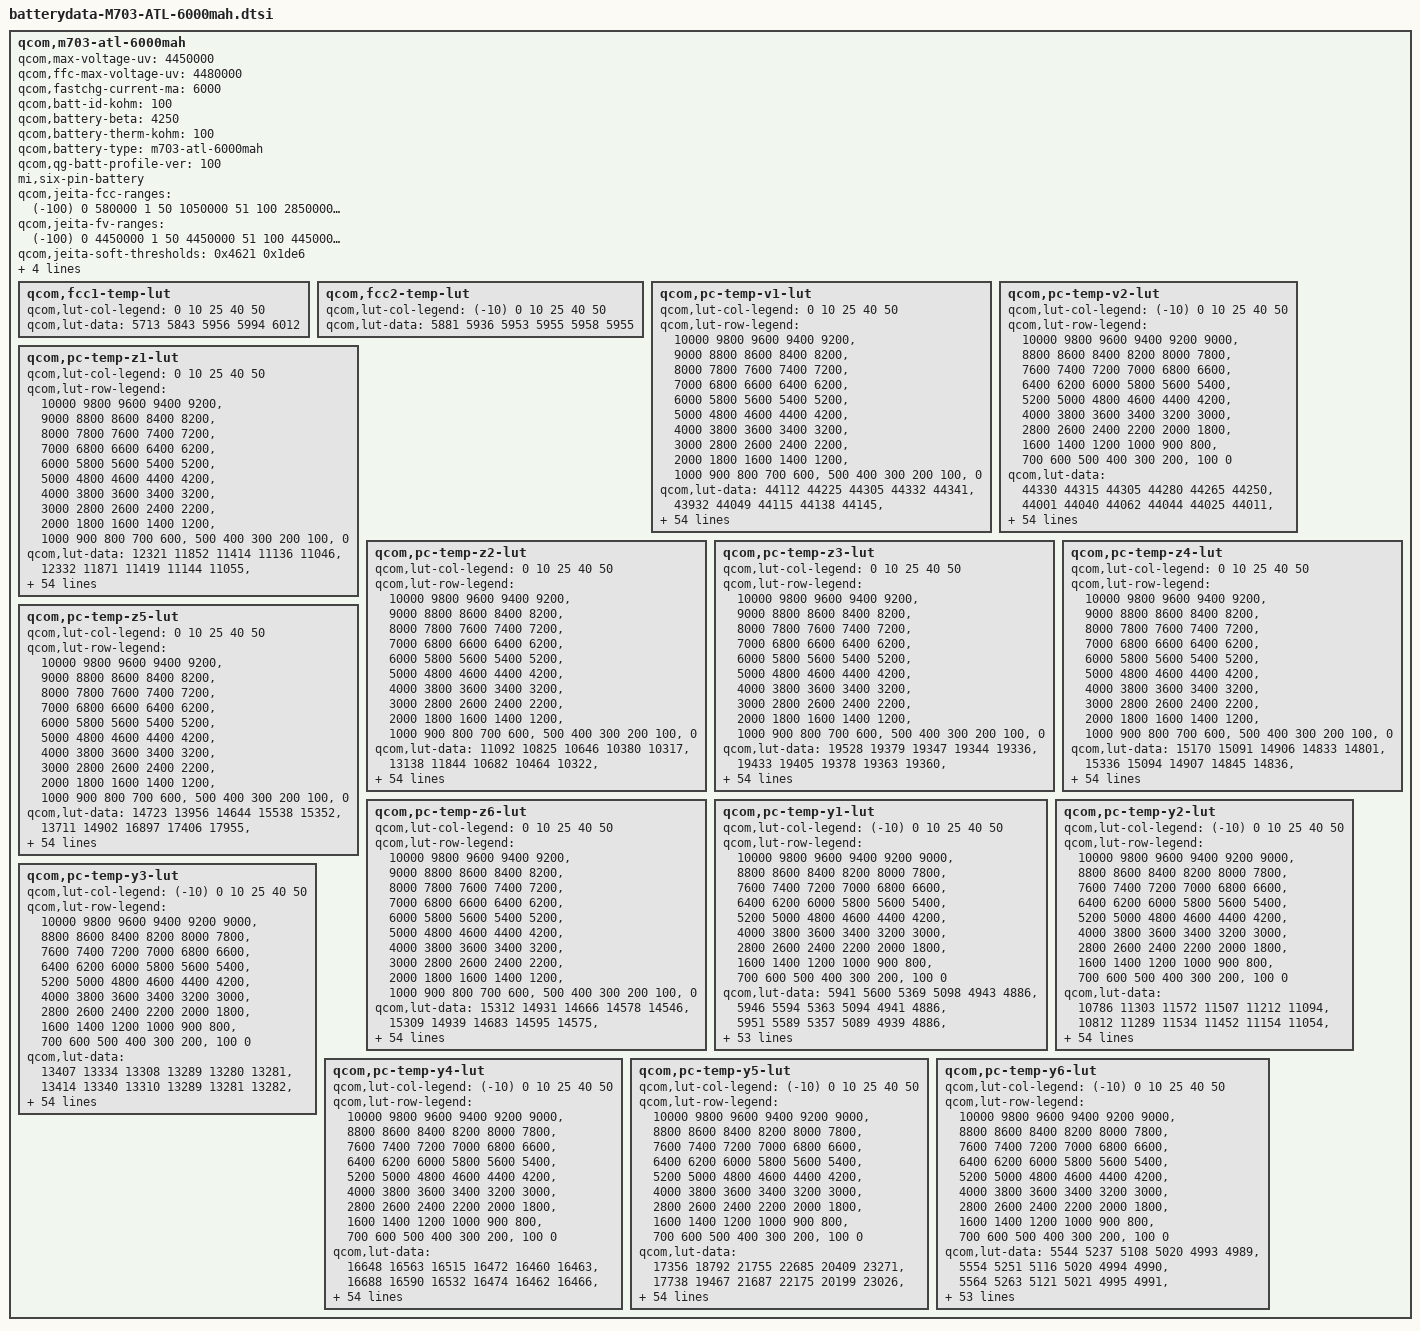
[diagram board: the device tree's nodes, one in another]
/*
 * Copyright (c) 2019, The Linux Foundation. All rights reserved.
 * Copyright (C) 2021 XiaoMi, Inc.
 *
 * This program is free software; you can redistribute it and/or modify
 * it under the terms of the GNU General Public License version 2 and
 * only version 2 as published by the Free Software Foundation.
 *
 * This program is distributed in the hope that it will be useful,
 * but WITHOUT ANY WARRANTY; without even the implied warranty of
 * MERCHANTABILITY or FITNESS FOR A PARTICULAR PURPOSE.  See the
 * GNU General Public License for more details.
 */

qcom,m703-atl-6000mah {
	qcom,max-voltage-uv = <4450000>;
	qcom,ffc-max-voltage-uv = <4480000>;
	//qcom,fg-cc-cv-threshold-uv = <4440000>;
	qcom,fastchg-current-ma = <6000>;
	qcom,batt-id-kohm = <100>;
	qcom,battery-beta = <4250>;
	qcom,battery-therm-kohm = <100>;
	qcom,battery-type = "m703-atl-6000mah";
	qcom,qg-batt-profile-ver = <100>;
	mi,six-pin-battery;

	qcom,jeita-fcc-ranges = <(-100)  0   580000
	                        1  50   1050000
				51  100  2850000
				101 150  4600000
				151 480  6000000
				481 580  2850000>;

	qcom,jeita-fv-ranges = <(-100)   0   4450000
                                1   50   4450000
				51  100  4450000
				101 150  4450000
				151 480  4480000
				481 580  4100000>;

	/* COOL = 15 degc, WARM = 48 degC */
	qcom,jeita-soft-thresholds = <0x4621 0x1de6>;
	/* COLD = -10 degC, HOT = 58 degC*/
	qcom,jeita-hard-thresholds = <0x6226 0x15f7>;
	/* COOL hys = 18 degC, WARM hys = 45 degC */
	qcom,jeita-soft-hys-thresholds = <0x4206 0x20b8>;
	qcom,jeita-soft-fcc-ua = <4600000 2900000>;
	qcom,jeita-soft-fv-uv = <4450000 4100000>;

	qcom,fcc1-temp-lut {
		qcom,lut-col-legend = <0 10 25 40 50>;
		qcom,lut-data = <5713 5843 5956 5994 6012>;
	};

	qcom,fcc2-temp-lut {
		qcom,lut-col-legend = <(-10) 0 10 25 40 50>;
		qcom,lut-data = <5881 5936 5953 5955 5958 5955>;
	};

	qcom,pc-temp-v1-lut {
		qcom,lut-col-legend = <0 10 25 40 50>;
		qcom,lut-row-legend = <10000 9800 9600 9400 9200>,
			<9000 8800 8600 8400 8200>,
			<8000 7800 7600 7400 7200>,
			<7000 6800 6600 6400 6200>,
			<6000 5800 5600 5400 5200>,
			<5000 4800 4600 4400 4200>,
			<4000 3800 3600 3400 3200>,
			<3000 2800 2600 2400 2200>,
			<2000 1800 1600 1400 1200>,
			<1000 900 800 700 600>,
			<500 400 300 200 100>,
			<0>;
		qcom,lut-data = <44112 44225 44305 44332 44341>,
			<43932 44049 44115 44138 44145>,
			<43712 43852 43919 43945 43953>,
			<43480 43638 43719 43747 43755>,
			<43249 43415 43513 43545 43552>,
			<43013 43185 43296 43334 43342>,
			<42777 42949 43065 43108 43117>,
			<42537 42710 42826 42872 42882>,
			<42299 42466 42586 42633 42644>,
			<42066 42224 42341 42388 42400>,
			<41836 41987 42100 42144 42157>,
			<41613 41754 41861 41904 41918>,
			<41393 41528 41627 41667 41682>,
			<41182 41307 41398 41435 41449>,
			<40980 41091 41173 41208 41219>,
			<40787 40886 40957 40988 40996>,
			<40593 40686 40748 40778 40781>,
			<40393 40493 40546 40574 40574>,
			<40197 40311 40360 40383 40381>,
			<40015 40122 40183 40208 40208>,
			<39852 39902 39984 40014 40021>,
			<39677 39661 39736 39753 39767>,
			<39430 39443 39488 39473 39485>,
			<39148 39242 39290 39274 39282>,
			<38976 39066 39117 39125 39134>,
			<38899 38939 38971 38994 39004>,
			<38839 38843 38853 38869 38875>,
			<38768 38753 38749 38756 38754>,
			<38693 38661 38648 38651 38647>,
			<38622 38571 38549 38553 38550>,
			<38556 38492 38461 38463 38462>,
			<38494 38418 38384 38384 38381>,
			<38438 38353 38314 38311 38306>,
			<38386 38297 38252 38241 38233>,
			<38338 38247 38196 38172 38163>,
			<38297 38202 38143 38105 38091>,
			<38260 38164 38092 38041 38020>,
			<38213 38120 38039 37975 37944>,
			<38139 38051 37968 37891 37849>,
			<38043 37954 37874 37784 37726>,
			<37935 37846 37769 37669 37598>,
			<37802 37719 37655 37556 37480>,
			<37649 37573 37521 37428 37352>,
			<37471 37401 37348 37257 37175>,
			<37304 37239 37201 37124 37054>,
			<37222 37138 37098 37047 36987>,
			<37188 37104 37068 37018 36960>,
			<37154 37084 37044 36992 36935>,
			<37121 37065 37025 36973 36911>,
			<37071 37017 36975 36913 36839>,
			<36890 36808 36737 36648 36551>,
			<36444 36353 36287 36204 36103>,
			<35857 35756 35698 35624 35520>,
			<35053 34929 34895 34832 34720>,
			<33706 33549 33645 33607 33478>,
			<30000 30000 30000 30000 30000>;
	};

	qcom,pc-temp-v2-lut {
		qcom,lut-col-legend = <(-10) 0 10 25 40 50>;
		qcom,lut-row-legend = <10000 9800 9600 9400 9200 9000>,
			<8800 8600 8400 8200 8000 7800>,
			<7600 7400 7200 7000 6800 6600>,
			<6400 6200 6000 5800 5600 5400>,
			<5200 5000 4800 4600 4400 4200>,
			<4000 3800 3600 3400 3200 3000>,
			<2800 2600 2400 2200 2000 1800>,
			<1600 1400 1200 1000 900 800>,
			<700 600 500 400 300 200>,
			<100 0>;
		qcom,lut-data = <44330 44315 44305 44280 44265 44250>,
			<44001 44040 44062 44044 44025 44011>,
			<43700 43782 43828 43815 43793 43781>,
			<43432 43546 43607 43594 43571 43561>,
			<43197 43334 43398 43381 43360 43352>,
			<42966 43119 43185 43164 43146 43139>,
			<42721 42884 42953 42931 42915 42910>,
			<42474 42640 42711 42691 42677 42674>,
			<42232 42395 42468 42449 42438 42436>,
			<41997 42147 42222 42204 42194 42194>,
			<41765 41902 41977 41960 41952 41952>,
			<41528 41663 41738 41721 41713 41713>,
			<41292 41431 41502 41486 41478 41476>,
			<41083 41209 41272 41255 41247 41244>,
			<40918 40997 41047 41029 41023 41020>,
			<40743 40791 40829 40810 40806 40803>,
			<40471 40592 40619 40600 40596 40592>,
			<40100 40396 40414 40397 40393 40387>,
			<39782 40170 40209 40203 40202 40195>,
			<39549 39888 40005 40025 40027 40019>,
			<39343 39603 39788 39835 39840 39833>,
			<39136 39357 39534 39585 39596 39594>,
			<38935 39130 39260 39300 39320 39325>,
			<38749 38933 39039 39075 39098 39105>,
			<38570 38761 38863 38902 38923 38930>,
			<38410 38608 38712 38754 38773 38779>,
			<38299 38472 38578 38623 38641 38646>,
			<38217 38349 38459 38508 38526 38530>,
			<38147 38237 38349 38402 38421 38422>,
			<38084 38130 38247 38303 38324 38321>,
			<38028 38039 38153 38213 38236 38229>,
			<37972 37973 38063 38131 38156 38149>,
			<37919 37921 37979 38055 38083 38076>,
			<37864 37877 37907 37982 38008 37999>,
			<37807 37841 37849 37914 37931 37915>,
			<37748 37806 37796 37844 37848 37823>,
			<37684 37765 37747 37762 37752 37717>,
			<37618 37722 37700 37671 37644 37598>,
			<37545 37665 37641 37581 37544 37492>,
			<37462 37577 37559 37498 37455 37404>,
			<37369 37461 37459 37412 37365 37317>,
			<37263 37324 37343 37309 37261 37213>,
			<37135 37161 37206 37189 37143 37093>,
			<37005 36995 37052 37056 37011 36960>,
			<36885 36840 36910 36939 36900 36849>,
			<36785 36749 36835 36880 36850 36800>,
			<36742 36720 36805 36867 36839 36788>,
			<36701 36681 36776 36851 36824 36772>,
			<36656 36634 36736 36827 36797 36744>,
			<36603 36552 36649 36759 36725 36651>,
			<36507 36330 36384 36515 36441 36327>,
			<36287 35891 35869 36032 35956 35829>,
			<35832 35254 35185 35396 35322 35183>,
			<35136 34325 34245 34537 34450 34285>,
			<34127 32820 32752 33249 33161 32941>,
			<32318 29011 28063 28283 28990 28511>;
	};

	qcom,pc-temp-z1-lut {
		qcom,lut-col-legend = <0 10 25 40 50>;
		qcom,lut-row-legend = <10000 9800 9600 9400 9200>,
			<9000 8800 8600 8400 8200>,
			<8000 7800 7600 7400 7200>,
			<7000 6800 6600 6400 6200>,
			<6000 5800 5600 5400 5200>,
			<5000 4800 4600 4400 4200>,
			<4000 3800 3600 3400 3200>,
			<3000 2800 2600 2400 2200>,
			<2000 1800 1600 1400 1200>,
			<1000 900 800 700 600>,
			<500 400 300 200 100>,
			<0>;
		qcom,lut-data = <12321 11852 11414 11136 11046>,
			<12332 11871 11419 11144 11055>,
			<12324 11873 11420 11149 11058>,
			<12314 11871 11417 11149 11058>,
			<12299 11868 11410 11145 11056>,
			<12287 11857 11402 11140 11053>,
			<12287 11839 11392 11136 11050>,
			<12293 11825 11382 11132 11047>,
			<12296 11812 11373 11128 11045>,
			<12280 11803 11365 11124 11043>,
			<12248 11799 11361 11121 11042>,
			<12230 11795 11358 11120 11042>,
			<12222 11790 11356 11119 11042>,
			<12216 11778 11353 11118 11041>,
			<12209 11769 11350 11116 11041>,
			<12201 11767 11348 11115 11041>,
			<12192 11768 11347 11115 11041>,
			<12181 11768 11346 11115 11042>,
			<12170 11765 11347 11115 11042>,
			<12165 11762 11349 11117 11043>,
			<12162 11761 11350 11118 11044>,
			<12161 11762 11349 11118 11045>,
			<12168 11763 11349 11118 11045>,
			<12179 11765 11349 11118 11046>,
			<12182 11766 11353 11120 11048>,
			<12181 11768 11358 11122 11051>,
			<12180 11772 11363 11126 11053>,
			<12182 11777 11368 11129 11056>,
			<12189 11784 11372 11133 11059>,
			<12193 11791 11376 11136 11061>,
			<12190 11792 11379 11139 11063>,
			<12184 11788 11383 11143 11066>,
			<12184 11786 11388 11146 11070>,
			<12185 11788 11393 11150 11073>,
			<12188 11793 11399 11155 11077>,
			<12191 11798 11404 11159 11080>,
			<12197 11806 11408 11163 11084>,
			<12205 11814 11412 11167 11088>,
			<12221 11823 11417 11171 11091>,
			<12241 11834 11425 11176 11094>,
			<12256 11840 11432 11181 11098>,
			<12269 11845 11438 11185 11101>,
			<12278 11847 11446 11188 11105>,
			<12287 11854 11456 11192 11107>,
			<12300 11866 11471 11198 11110>,
			<12289 11875 11476 11201 11112>,
			<12300 11873 11477 11200 11111>,
			<12295 11859 11473 11200 11112>,
			<12289 11865 11479 11202 11113>,
			<12308 11876 11483 11205 11116>,
			<12303 11878 11491 11211 11119>,
			<12314 11884 11504 11216 11124>,
			<12338 11904 11510 11223 11130>,
			<12365 11922 11525 11234 11139>,
			<12365 11922 11525 11234 11139>,
			<12365 11922 11525 11234 11139>;
	};

	qcom,pc-temp-z2-lut {
		qcom,lut-col-legend = <0 10 25 40 50>;
		qcom,lut-row-legend = <10000 9800 9600 9400 9200>,
			<9000 8800 8600 8400 8200>,
			<8000 7800 7600 7400 7200>,
			<7000 6800 6600 6400 6200>,
			<6000 5800 5600 5400 5200>,
			<5000 4800 4600 4400 4200>,
			<4000 3800 3600 3400 3200>,
			<3000 2800 2600 2400 2200>,
			<2000 1800 1600 1400 1200>,
			<1000 900 800 700 600>,
			<500 400 300 200 100>,
			<0>;
		qcom,lut-data = <11092 10825 10646 10380 10317>,
			<13138 11844 10682 10464 10322>,
			<11666 11854 10702 10517 10385>,
			<10655 11217 10702 10523 10416>,
			<10618 10785 10696 10510 10442>,
			<10599 10750 10684 10494 10460>,
			<10577 10725 10644 10470 10441>,
			<10554 10699 10598 10438 10398>,
			<10539 10673 10564 10413 10376>,
			<10530 10654 10536 10391 10362>,
			<10525 10643 10528 10380 10353>,
			<10524 10636 10531 10380 10347>,
			<10529 10635 10536 10382 10343>,
			<10538 10640 10538 10385 10344>,
			<10552 10648 10539 10394 10348>,
			<10572 10667 10541 10404 10356>,
			<10593 10696 10553 10414 10373>,
			<10612 10717 10570 10423 10396>,
			<10633 10732 10582 10423 10397>,
			<10660 10744 10594 10412 10370>,
			<10701 10755 10615 10405 10350>,
			<10728 10764 10692 10581 10494>,
			<10732 10765 10766 10853 10764>,
			<10731 10740 10746 10867 10810>,
			<10729 10713 10664 10653 10636>,
			<10719 10714 10626 10512 10497>,
			<10709 10728 10646 10573 10534>,
			<10709 10736 10669 10672 10613>,
			<10716 10736 10667 10670 10610>,
			<10723 10736 10648 10547 10459>,
			<10730 10737 10628 10437 10321>,
			<10737 10742 10610 10386 10268>,
			<10746 10749 10595 10351 10229>,
			<10757 10762 10597 10347 10216>,
			<10770 10781 10612 10359 10207>,
			<10781 10797 10634 10378 10203>,
			<10792 10809 10669 10421 10229>,
			<10805 10821 10711 10486 10291>,
			<10824 10841 10742 10545 10361>,
			<10842 10864 10769 10610 10459>,
			<10850 10876 10787 10644 10524>,
			<10854 10880 10797 10641 10531>,
			<10865 10886 10804 10639 10533>,
			<10915 10908 10808 10663 10582>,
			<11239 11110 10851 10654 10525>,
			<10862 11177 10882 10528 10392>,
			<10736 11168 10871 10487 10378>,
			<10700 11257 10870 10506 10379>,
			<10681 11814 10852 10533 10425>,
			<10541 11934 10908 10580 10496>,
			<10548 11919 10912 10507 10411>,
			<10397 11851 10824 10344 10229>,
			<10274 11668 10771 10297 10176>,
			<9974 11392 10714 10233 10108>,
			<9974 11392 10714 10233 10108>,
			<9974 11392 10714 10233 10108>;
	};

	qcom,pc-temp-z3-lut {
		qcom,lut-col-legend = <0 10 25 40 50>;
		qcom,lut-row-legend = <10000 9800 9600 9400 9200>,
			<9000 8800 8600 8400 8200>,
			<8000 7800 7600 7400 7200>,
			<7000 6800 6600 6400 6200>,
			<6000 5800 5600 5400 5200>,
			<5000 4800 4600 4400 4200>,
			<4000 3800 3600 3400 3200>,
			<3000 2800 2600 2400 2200>,
			<2000 1800 1600 1400 1200>,
			<1000 900 800 700 600>,
			<500 400 300 200 100>,
			<0>;
		qcom,lut-data = <19528 19379 19347 19344 19336>,
			<19433 19405 19378 19363 19360>,
			<19539 19430 19399 19376 19369>,
			<19613 19474 19410 19385 19378>,
			<19635 19503 19418 19394 19388>,
			<19648 19510 19424 19400 19395>,
			<19656 19515 19430 19405 19400>,
			<19662 19518 19433 19410 19404>,
			<19664 19522 19435 19413 19407>,
			<19664 19523 19436 19416 19409>,
			<19663 19522 19437 19418 19410>,
			<19661 19521 19433 19416 19408>,
			<19660 19519 19429 19411 19403>,
			<19658 19516 19427 19408 19400>,
			<19654 19512 19425 19405 19397>,
			<19649 19508 19422 19402 19395>,
			<19646 19504 19420 19399 19392>,
			<19642 19499 19417 19394 19388>,
			<19637 19495 19414 19390 19384>,
			<19633 19492 19410 19384 19377>,
			<19627 19499 19410 19381 19373>,
			<19624 19516 19420 19389 19377>,
			<19631 19522 19432 19402 19385>,
			<19645 19512 19428 19401 19385>,
			<19651 19501 19410 19385 19376>,
			<19639 19500 19402 19374 19369>,
			<19626 19500 19409 19392 19387>,
			<19624 19501 19420 19420 19418>,
			<19624 19506 19428 19426 19425>,
			<19624 19513 19437 19422 19418>,
			<19622 19514 19440 19418 19410>,
			<19620 19511 19436 19410 19403>,
			<19618 19509 19430 19401 19394>,
			<19615 19505 19425 19393 19386>,
			<19612 19501 19420 19387 19376>,
			<19609 19498 19415 19381 19367>,
			<19605 19495 19411 19374 19360>,
			<19601 19492 19408 19369 19355>,
			<19595 19488 19406 19369 19354>,
			<19588 19484 19405 19371 19356>,
			<19581 19480 19403 19372 19359>,
			<19574 19475 19398 19372 19362>,
			<19564 19469 19394 19371 19365>,
			<19546 19460 19392 19375 19370>,
			<19489 19434 19382 19372 19366>,
			<19333 19417 19376 19359 19356>,
			<19283 19415 19370 19351 19350>,
			<19278 19391 19369 19348 19341>,
			<19274 19302 19356 19338 19332>,
			<19261 19298 19350 19335 19330>,
			<19261 19306 19369 19352 19339>,
			<19262 19295 19378 19367 19356>,
			<19262 19297 19381 19365 19354>,
			<19268 19303 19379 19366 19356>,
			<19268 19303 19379 19366 19356>,
			<19268 19303 19379 19366 19356>;
	};

	qcom,pc-temp-z4-lut {
		qcom,lut-col-legend = <0 10 25 40 50>;
		qcom,lut-row-legend = <10000 9800 9600 9400 9200>,
			<9000 8800 8600 8400 8200>,
			<8000 7800 7600 7400 7200>,
			<7000 6800 6600 6400 6200>,
			<6000 5800 5600 5400 5200>,
			<5000 4800 4600 4400 4200>,
			<4000 3800 3600 3400 3200>,
			<3000 2800 2600 2400 2200>,
			<2000 1800 1600 1400 1200>,
			<1000 900 800 700 600>,
			<500 400 300 200 100>,
			<0>;
		qcom,lut-data = <15170 15091 14906 14833 14801>,
			<15336 15094 14907 14845 14836>,
			<15293 15067 14902 14838 14829>,
			<15238 15019 14884 14827 14819>,
			<15167 14974 14850 14806 14802>,
			<15092 14932 14821 14785 14784>,
			<15032 14892 14798 14768 14770>,
			<14981 14859 14778 14753 14757>,
			<14940 14831 14760 14739 14744>,
			<14906 14808 14744 14724 14731>,
			<14879 14790 14731 14712 14719>,
			<14856 14775 14718 14703 14711>,
			<14837 14762 14708 14696 14705>,
			<14821 14751 14703 14692 14701>,
			<14807 14742 14699 14689 14699>,
			<14794 14734 14696 14687 14698>,
			<14788 14729 14694 14685 14696>,
			<14788 14728 14692 14683 14695>,
			<14788 14728 14690 14679 14692>,
			<14786 14729 14688 14674 14684>,
			<14776 14735 14688 14672 14679>,
			<14767 14749 14708 14696 14703>,
			<14793 14767 14739 14738 14750>,
			<14848 14799 14765 14763 14769>,
			<14871 14827 14794 14780 14776>,
			<14861 14826 14804 14788 14780>,
			<14845 14808 14787 14760 14755>,
			<14832 14789 14760 14714 14709>,
			<14818 14771 14740 14698 14694>,
			<14807 14756 14722 14693 14691>,
			<14797 14750 14713 14690 14689>,
			<14789 14746 14710 14687 14685>,
			<14784 14745 14708 14685 14681>,
			<14781 14744 14706 14683 14678>,
			<14778 14743 14705 14681 14675>,
			<14773 14741 14705 14679 14673>,
			<14768 14738 14703 14679 14671>,
			<14762 14733 14702 14679 14671>,
			<14755 14729 14702 14680 14672>,
			<14747 14724 14704 14688 14685>,
			<14737 14717 14705 14693 14694>,
			<14721 14705 14698 14688 14687>,
			<14706 14692 14688 14682 14680>,
			<14690 14680 14682 14682 14686>,
			<14670 14656 14664 14668 14675>,
			<14812 14647 14650 14654 14652>,
			<14864 14644 14647 14654 14648>,
			<14865 14659 14638 14646 14644>,
			<14864 14754 14636 14637 14633>,
			<14872 14756 14635 14627 14623>,
			<14868 14749 14632 14647 14662>,
			<14875 14769 14635 14655 14672>,
			<14877 14768 14636 14663 14681>,
			<14880 14767 14642 14667 14687>,
			<14880 14767 14642 14667 14687>,
			<14880 14767 14642 14667 14687>;
	};

	qcom,pc-temp-z5-lut {
		qcom,lut-col-legend = <0 10 25 40 50>;
		qcom,lut-row-legend = <10000 9800 9600 9400 9200>,
			<9000 8800 8600 8400 8200>,
			<8000 7800 7600 7400 7200>,
			<7000 6800 6600 6400 6200>,
			<6000 5800 5600 5400 5200>,
			<5000 4800 4600 4400 4200>,
			<4000 3800 3600 3400 3200>,
			<3000 2800 2600 2400 2200>,
			<2000 1800 1600 1400 1200>,
			<1000 900 800 700 600>,
			<500 400 300 200 100>,
			<0>;
		qcom,lut-data = <14723 13956 14644 15538 15352>,
			<13711 14902 16897 17406 17955>,
			<15875 15934 18473 19144 19526>,
			<17787 18031 19295 20396 21149>,
			<18834 19735 19900 21413 22751>,
			<19714 20441 20499 22368 24262>,
			<20678 21043 21152 23348 25636>,
			<21729 21905 21829 24419 26959>,
			<22800 23012 22582 25761 28598>,
			<23826 24082 23460 27719 30826>,
			<24852 25033 24354 29615 32708>,
			<25984 25930 25251 31076 33773>,
			<27257 26789 26104 32342 34642>,
			<28464 27618 26861 33487 35613>,
			<29498 28497 27571 34563 37090>,
			<30581 29697 28218 35306 38507>,
			<31672 30890 28830 35861 39716>,
			<32988 31146 29339 36375 40765>,
			<34268 30676 29643 36462 41079>,
			<35125 30256 29845 35991 40877>,
			<36120 34736 30460 35936 40796>,
			<37711 45430 35732 41425 42869>,
			<42531 49165 41360 49846 46590>,
			<49886 40917 38329 48492 45710>,
			<52168 31491 27186 32098 32374>,
			<45586 29395 21983 21243 22191>,
			<38116 28569 22429 24614 27727>,
			<37256 28326 23397 30611 38087>,
			<38228 30851 25607 33567 40981>,
			<39554 35286 30298 35300 40605>,
			<41407 38612 33572 36013 40145>,
			<43688 41520 34953 35115 39393>,
			<45467 43531 35907 33662 37936>,
			<46955 44634 36664 33271 36533>,
			<48021 45380 37328 33216 33634>,
			<48533 45512 37771 33187 31434>,
			<48888 45327 38051 33106 30889>,
			<49011 45117 38232 33012 30572>,
			<48975 44965 38262 33472 31007>,
			<48885 44714 38163 36020 34043>,
			<48531 44365 37936 37698 36310>,
			<47341 43561 35220 35355 36131>,
			<46688 42518 32955 32931 35907>,
			<46422 41163 35157 38770 43167>,
			<43327 45854 36224 40839 44602>,
			<17740 39951 35462 32032 35253>,
			<12567 38785 31292 25427 27514>,
			<12373 26658 33535 25861 24017>,
			<12290 13368 27352 24967 24785>,
			<12074 13222 25330 28192 30916>,
			<12131 13626 35378 34874 28993>,
			<12069 13009 33613 29019 24152>,
			<12016 13018 33019 23511 19830>,
			<12470 13647 27472 20398 17224>,
			<12470 13647 27472 20398 17224>,
			<12470 13647 27472 20398 17224>;
	};

	qcom,pc-temp-z6-lut {
		qcom,lut-col-legend = <0 10 25 40 50>;
		qcom,lut-row-legend = <10000 9800 9600 9400 9200>,
			<9000 8800 8600 8400 8200>,
			<8000 7800 7600 7400 7200>,
			<7000 6800 6600 6400 6200>,
			<6000 5800 5600 5400 5200>,
			<5000 4800 4600 4400 4200>,
			<4000 3800 3600 3400 3200>,
			<3000 2800 2600 2400 2200>,
			<2000 1800 1600 1400 1200>,
			<1000 900 800 700 600>,
			<500 400 300 200 100>,
			<0>;
		qcom,lut-data = <15312 14931 14666 14578 14546>,
			<15309 14939 14683 14595 14575>,
			<15315 14933 14690 14600 14578>,
			<15314 14922 14686 14599 14578>,
			<15281 14912 14674 14594 14576>,
			<15231 14892 14663 14588 14572>,
			<15192 14867 14654 14584 14569>,
			<15158 14847 14645 14579 14565>,
			<15129 14829 14637 14574 14561>,
			<15103 14814 14630 14569 14557>,
			<15081 14801 14622 14565 14552>,
			<15062 14790 14614 14559 14547>,
			<15046 14780 14607 14554 14542>,
			<15032 14770 14603 14550 14538>,
			<15018 14762 14600 14547 14536>,
			<15006 14755 14597 14544 14534>,
			<14996 14750 14594 14541 14531>,
			<14988 14746 14591 14537 14529>,
			<14981 14743 14589 14533 14525>,
			<14973 14741 14586 14528 14518>,
			<14964 14747 14586 14525 14514>,
			<14959 14762 14601 14542 14527>,
			<14973 14773 14621 14568 14552>,
			<15005 14783 14628 14573 14558>,
			<15018 14790 14633 14573 14557>,
			<15009 14789 14635 14573 14556>,
			<14996 14783 14631 14571 14555>,
			<14990 14777 14627 14567 14553>,
			<14985 14773 14624 14564 14550>,
			<14981 14771 14621 14561 14546>,
			<14977 14769 14619 14557 14542>,
			<14973 14767 14617 14552 14537>,
			<14971 14766 14614 14547 14531>,
			<14971 14765 14611 14543 14526>,
			<14970 14764 14609 14539 14520>,
			<14969 14762 14607 14536 14514>,
			<14967 14761 14605 14532 14510>,
			<14966 14760 14603 14530 14507>,
			<14966 14760 14604 14530 14507>,
			<14966 14759 14605 14535 14514>,
			<14965 14758 14606 14538 14519>,
			<14964 14755 14602 14536 14518>,
			<14962 14750 14597 14534 14517>,
			<14957 14747 14596 14536 14522>,
			<14930 14731 14586 14529 14515>,
			<14919 14722 14578 14517 14501>,
			<14916 14718 14574 14513 14496>,
			<14914 14715 14570 14508 14490>,
			<14915 14712 14564 14499 14480>,
			<14919 14713 14561 14493 14475>,
			<14925 14720 14572 14512 14497>,
			<14934 14727 14581 14525 14513>,
			<14945 14734 14585 14529 14518>,
			<14961 14745 14590 14534 14524>,
			<14961 14745 14590 14534 14524>,
			<14961 14745 14590 14534 14524>;
	};

	qcom,pc-temp-y1-lut {
		qcom,lut-col-legend = <(-10) 0 10 25 40 50>;
		qcom,lut-row-legend = <10000 9800 9600 9400 9200 9000>,
			<8800 8600 8400 8200 8000 7800>,
			<7600 7400 7200 7000 6800 6600>,
			<6400 6200 6000 5800 5600 5400>,
			<5200 5000 4800 4600 4400 4200>,
			<4000 3800 3600 3400 3200 3000>,
			<2800 2600 2400 2200 2000 1800>,
			<1600 1400 1200 1000 900 800>,
			<700 600 500 400 300 200>,
			<100 0>;
		qcom,lut-data = <5941 5600 5369 5098 4943 4886>,
			<5946 5594 5363 5094 4941 4886>,
			<5951 5589 5357 5089 4939 4886>,
			<5956 5586 5352 5084 4937 4885>,
			<5959 5583 5347 5079 4935 4885>,
			<5960 5580 5342 5076 4933 4884>,
			<5959 5582 5338 5075 4932 4883>,
			<5957 5586 5334 5074 4931 4882>,
			<5958 5587 5332 5072 4929 4881>,
			<5970 5580 5332 5070 4929 4881>,
			<5981 5575 5332 5068 4928 4880>,
			<5978 5579 5331 5066 4927 4880>,
			<5970 5586 5329 5065 4926 4880>,
			<5971 5589 5326 5064 4926 4880>,
			<5985 5585 5322 5063 4926 4880>,
			<5998 5582 5319 5062 4926 4880>,
			<5996 5579 5320 5062 4926 4880>,
			<5986 5575 5323 5062 4926 4880>,
			<5980 5575 5324 5062 4927 4881>,
			<5979 5580 5322 5064 4927 4881>,
			<5981 5585 5323 5066 4929 4882>,
			<5987 5590 5325 5067 4930 4883>,
			<5999 5596 5329 5070 4931 4884>,
			<6004 5598 5331 5072 4932 4885>,
			<6003 5593 5330 5075 4934 4886>,
			<6001 5586 5329 5078 4936 4888>,
			<5996 5587 5330 5081 4937 4890>,
			<5983 5592 5334 5084 4939 4892>,
			<5974 5595 5336 5087 4941 4894>,
			<5983 5596 5337 5090 4943 4896>,
			<5999 5596 5338 5093 4946 4898>,
			<6001 5594 5341 5097 4948 4899>,
			<5984 5591 5347 5100 4950 4901>,
			<5969 5590 5349 5103 4953 4903>,
			<5975 5597 5349 5105 4955 4904>,
			<5988 5603 5349 5108 4957 4905>,
			<5991 5601 5351 5110 4958 4907>,
			<5980 5595 5353 5112 4959 4908>,
			<5968 5593 5355 5114 4960 4909>,
			<5965 5596 5359 5115 4961 4909>,
			<5964 5599 5363 5117 4962 4910>,
			<5963 5605 5367 5120 4963 4911>,
			<5966 5611 5375 5124 4965 4913>,
			<5970 5609 5375 5127 4966 4915>,
			<5979 5615 5376 5131 4969 4916>,
			<5985 5603 5385 5137 4971 4918>,
			<5991 5616 5379 5137 4971 4918>,
			<6035 5620 5385 5137 4970 4918>,
			<6049 5619 5395 5135 4970 4918>,
			<6054 5625 5394 5138 4971 4919>,
			<6039 5634 5397 5136 4972 4921>,
			<6106 5666 5406 5140 4975 4923>,
			<6189 5720 5414 5149 4979 4927>,
			<6251 5811 5432 5159 4985 4933>,
			<6251 5811 5432 5159 4985 4933>,
			<6251 5811 5432 5159 4985 4933>;
	};

	qcom,pc-temp-y2-lut {
		qcom,lut-col-legend = <(-10) 0 10 25 40 50>;
		qcom,lut-row-legend = <10000 9800 9600 9400 9200 9000>,
			<8800 8600 8400 8200 8000 7800>,
			<7600 7400 7200 7000 6800 6600>,
			<6400 6200 6000 5800 5600 5400>,
			<5200 5000 4800 4600 4400 4200>,
			<4000 3800 3600 3400 3200 3000>,
			<2800 2600 2400 2200 2000 1800>,
			<1600 1400 1200 1000 900 800>,
			<700 600 500 400 300 200>,
			<100 0>;
		qcom,lut-data = <10786 11303 11572 11507 11212 11094>,
			<10812 11289 11534 11452 11154 11054>,
			<10858 11271 11496 11398 11093 11010>,
			<10909 11251 11457 11347 11034 10967>,
			<10952 11230 11418 11301 10984 10930>,
			<10973 11207 11379 11265 10950 10904>,
			<10975 11181 11336 11236 10930 10887>,
			<10974 11154 11295 11212 10915 10874>,
			<10972 11136 11260 11190 10904 10860>,
			<10963 11123 11226 11168 10896 10845>,
			<10955 11117 11207 11151 10889 10830>,
			<10996 11128 11206 11136 10880 10814>,
			<11094 11158 11208 11124 10872 10800>,
			<11128 11199 11213 11121 10863 10788>,
			<11079 11273 11231 11127 10850 10778>,
			<11028 11326 11260 11136 10843 10772>,
			<11049 11326 11322 11148 10857 10778>,
			<11124 11322 11417 11170 10892 10792>,
			<11163 11325 11481 11212 10936 10811>,
			<11166 11362 11532 11335 11033 10863>,
			<11165 11401 11560 11429 11110 10919>,
			<11160 11410 11551 11428 11109 10973>,
			<11150 11413 11531 11417 11092 11037>,
			<11129 11418 11528 11414 11095 11059>,
			<10672 11434 11549 11421 11131 11075>,
			<10001 11454 11574 11432 11168 11093>,
			<9809 11465 11589 11447 11191 11105>,
			<9756 11474 11602 11471 11218 11121>,
			<9729 11483 11618 11498 11237 11142>,
			<9719 11498 11644 11538 11253 11191>,
			<9713 11510 11666 11574 11274 11236>,
			<9706 11506 11675 11592 11315 11245>,
			<9699 11486 11681 11605 11373 11247>,
			<9692 11456 11682 11612 11395 11255>,
			<9686 11396 11674 11618 11397 11281>,
			<9682 11316 11658 11622 11396 11301>,
			<9678 11244 11631 11601 11372 11289>,
			<9676 11173 11584 11551 11321 11254>,
			<9674 11078 11535 11531 11296 11225>,
			<9673 10807 11489 11535 11285 11189>,
			<9671 10436 11435 11539 11272 11158>,
			<9670 10141 11358 11527 11258 11154>,
			<9669 9778 11255 11504 11239 11153>,
			<9667 9708 11134 11492 11202 11111>,
			<9666 9691 10986 11459 11131 10985>,
			<9665 9680 10878 11360 11050 10866>,
			<9664 9678 10843 11351 11070 10874>,
			<9662 9674 10758 11354 11082 10882>,
			<9661 9670 10674 11367 11096 10952>,
			<9659 9667 10585 11381 11101 10960>,
			<9656 9663 10109 11365 10997 10865>,
			<9652 9658 9767 11300 10926 10790>,
			<9651 9653 9683 11186 10854 10684>,
			<9649 9652 9661 11070 10713 10527>,
			<9649 9652 9661 11070 10713 10527>,
			<9649 9652 9661 11070 10713 10527>;
	};

	qcom,pc-temp-y3-lut {
		qcom,lut-col-legend = <(-10) 0 10 25 40 50>;
		qcom,lut-row-legend = <10000 9800 9600 9400 9200 9000>,
			<8800 8600 8400 8200 8000 7800>,
			<7600 7400 7200 7000 6800 6600>,
			<6400 6200 6000 5800 5600 5400>,
			<5200 5000 4800 4600 4400 4200>,
			<4000 3800 3600 3400 3200 3000>,
			<2800 2600 2400 2200 2000 1800>,
			<1600 1400 1200 1000 900 800>,
			<700 600 500 400 300 200>,
			<100 0>;
		qcom,lut-data = <13407 13334 13308 13289 13280 13281>,
			<13414 13340 13310 13289 13281 13282>,
			<13420 13346 13313 13290 13282 13283>,
			<13426 13351 13315 13291 13283 13283>,
			<13431 13356 13318 13292 13284 13284>,
			<13435 13360 13319 13292 13284 13284>,
			<13438 13362 13320 13293 13285 13285>,
			<13440 13364 13322 13294 13286 13286>,
			<13440 13365 13322 13294 13286 13286>,
			<13438 13368 13322 13295 13286 13287>,
			<13435 13369 13323 13295 13287 13287>,
			<13432 13369 13324 13295 13287 13288>,
			<13427 13368 13325 13296 13288 13288>,
			<13422 13367 13326 13297 13288 13288>,
			<13417 13362 13327 13297 13289 13288>,
			<13411 13357 13327 13297 13290 13289>,
			<13407 13355 13325 13298 13290 13290>,
			<13403 13354 13321 13299 13292 13290>,
			<13399 13352 13320 13300 13293 13291>,
			<13394 13348 13320 13300 13294 13292>,
			<13389 13343 13321 13300 13296 13292>,
			<13384 13339 13318 13298 13293 13290>,
			<13380 13335 13312 13293 13287 13286>,
			<13374 13332 13309 13290 13284 13283>,
			<13359 13330 13306 13289 13282 13281>,
			<13343 13327 13305 13289 13281 13280>,
			<13341 13326 13304 13288 13281 13280>,
			<13344 13325 13304 13288 13281 13280>,
			<13349 13323 13304 13288 13281 13280>,
			<13356 13319 13303 13287 13281 13279>,
			<13367 13314 13303 13287 13281 13278>,
			<13379 13313 13302 13287 13281 13278>,
			<13394 13312 13300 13287 13281 13279>,
			<13411 13312 13299 13287 13281 13280>,
			<13431 13316 13299 13287 13281 13280>,
			<13457 13324 13298 13287 13282 13281>,
			<13487 13329 13299 13286 13282 13281>,
			<13523 13333 13302 13285 13281 13280>,
			<13565 13338 13304 13284 13281 13280>,
			<13609 13342 13305 13285 13282 13281>,
			<13659 13346 13306 13287 13283 13282>,
			<13714 13354 13308 13287 13283 13282>,
			<13773 13368 13312 13288 13282 13281>,
			<13845 13389 13314 13287 13282 13281>,
			<13937 13423 13317 13286 13282 13281>,
			<14066 13474 13322 13291 13287 13285>,
			<14141 13499 13322 13293 13289 13287>,
			<14220 13545 13328 13296 13291 13288>,
			<14369 13626 13336 13299 13292 13290>,
			<14610 13743 13346 13299 13291 13289>,
			<15157 13942 13357 13296 13288 13284>,
			<16928 14464 13390 13296 13288 13287>,
			<21753 16752 13509 13299 13291 13292>,
			<39798 25962 14162 13307 13299 13300>,
			<39798 25962 14162 13307 13299 13300>,
			<39798 25962 14162 13307 13299 13300>;
	};

	qcom,pc-temp-y4-lut {
		qcom,lut-col-legend = <(-10) 0 10 25 40 50>;
		qcom,lut-row-legend = <10000 9800 9600 9400 9200 9000>,
			<8800 8600 8400 8200 8000 7800>,
			<7600 7400 7200 7000 6800 6600>,
			<6400 6200 6000 5800 5600 5400>,
			<5200 5000 4800 4600 4400 4200>,
			<4000 3800 3600 3400 3200 3000>,
			<2800 2600 2400 2200 2000 1800>,
			<1600 1400 1200 1000 900 800>,
			<700 600 500 400 300 200>,
			<100 0>;
		qcom,lut-data = <16648 16563 16515 16472 16460 16463>,
			<16688 16590 16532 16474 16462 16466>,
			<16751 16629 16549 16475 16464 16469>,
			<16820 16671 16564 16477 16466 16472>,
			<16879 16705 16575 16478 16467 16474>,
			<16911 16720 16579 16478 16468 16475>,
			<16917 16717 16577 16478 16467 16474>,
			<16920 16712 16571 16478 16467 16473>,
			<16927 16707 16568 16478 16467 16472>,
			<16943 16701 16566 16479 16468 16472>,
			<16963 16697 16565 16481 16468 16472>,
			<16981 16702 16567 16483 16469 16471>,
			<16999 16718 16571 16487 16471 16471>,
			<17027 16740 16578 16491 16473 16472>,
			<17092 16785 16589 16496 16476 16473>,
			<17148 16829 16605 16503 16479 16475>,
			<17095 16856 16639 16512 16483 16478>,
			<16915 16877 16683 16523 16489 16482>,
			<16802 16876 16700 16541 16498 16489>,
			<16771 16803 16701 16578 16522 16509>,
			<16749 16714 16695 16605 16539 16523>,
			<16714 16661 16654 16581 16527 16514>,
			<16666 16618 16577 16523 16499 16492>,
			<16643 16589 16537 16492 16481 16478>,
			<16650 16570 16519 16479 16470 16469>,
			<16662 16555 16509 16472 16464 16465>,
			<16669 16542 16505 16472 16464 16465>,
			<16677 16531 16502 16473 16465 16464>,
			<16681 16521 16501 16475 16467 16465>,
			<16682 16512 16499 16478 16471 16468>,
			<16682 16506 16498 16483 16477 16474>,
			<16684 16508 16494 16488 16485 16482>,
			<16689 16519 16487 16493 16494 16491>,
			<16696 16531 16485 16495 16500 16498>,
			<16702 16540 16487 16495 16502 16503>,
			<16709 16550 16489 16495 16504 16506>,
			<16715 16566 16495 16489 16498 16501>,
			<16722 16589 16505 16471 16484 16487>,
			<16727 16606 16513 16464 16478 16482>,
			<16728 16615 16519 16466 16482 16492>,
			<16729 16622 16524 16470 16487 16504>,
			<16727 16625 16533 16474 16490 16508>,
			<16714 16627 16544 16478 16490 16506>,
			<16706 16624 16550 16472 16470 16479>,
			<16707 16619 16557 16467 16451 16454>,
			<16716 16627 16563 16477 16477 16500>,
			<16720 16628 16558 16487 16512 16537>,
			<16722 16646 16577 16517 16550 16575>,
			<16747 16671 16605 16557 16587 16609>,
			<16772 16703 16643 16584 16598 16607>,
			<16830 16728 16664 16537 16516 16517>,
			<17097 16766 16669 16501 16486 16494>,
			<18022 17339 16722 16508 16486 16489>,
			<24033 24961 16910 16536 16488 16488>,
			<24033 24961 16910 16536 16488 16488>,
			<24033 24961 16910 16536 16488 16488>;
	};

	qcom,pc-temp-y5-lut {
		qcom,lut-col-legend = <(-10) 0 10 25 40 50>;
		qcom,lut-row-legend = <10000 9800 9600 9400 9200 9000>,
			<8800 8600 8400 8200 8000 7800>,
			<7600 7400 7200 7000 6800 6600>,
			<6400 6200 6000 5800 5600 5400>,
			<5200 5000 4800 4600 4400 4200>,
			<4000 3800 3600 3400 3200 3000>,
			<2800 2600 2400 2200 2000 1800>,
			<1600 1400 1200 1000 900 800>,
			<700 600 500 400 300 200>,
			<100 0>;
		qcom,lut-data = <17356 18792 21755 22685 20409 23271>,
			<17738 19467 21687 22175 20199 23026>,
			<18523 20208 21534 21486 19981 22724>,
			<19441 20894 21351 20758 19770 22428>,
			<20222 21405 21196 20132 19575 22207>,
			<20595 21618 21128 19750 19409 22124>,
			<20602 21545 20959 19573 19284 22224>,
			<20588 21361 20632 19432 19163 22372>,
			<20533 21140 20352 19244 18984 22402>,
			<20187 20759 19739 18622 18701 22375>,
			<19692 20262 19071 18049 18359 22329>,
			<19071 19614 18583 17806 17907 21685>,
			<18328 18802 18119 17558 17399 20492>,
			<18215 17993 17625 17189 17103 20064>,
			<20447 17036 17038 16531 17009 19768>,
			<22768 16450 16590 15995 17028 19375>,
			<22844 17821 16350 15769 16976 18835>,
			<22495 20997 16201 15620 16784 18154>,
			<22345 22524 16603 15621 16669 17567>,
			<22805 22996 19641 16006 16528 16966>,
			<23360 23304 22577 16671 16497 16612>,
			<23390 23555 23517 18266 17478 17768>,
			<23150 23759 24111 20706 19335 20222>,
			<22720 23804 24217 21902 20052 20984>,
			<19063 23632 23840 22502 20161 20874>,
			<14037 23484 23483 22827 20135 20686>,
			<12821 23650 23709 22756 19823 20429>,
			<12594 24076 24354 22505 19272 20020>,
			<12510 24169 24786 22287 18921 19398>,
			<12624 21930 25059 22021 18669 18007>,
			<12871 18992 25214 21835 18503 16909>,
			<13080 17673 24941 22058 18470 16987>,
			<13318 16797 24073 22769 18538 17481>,
			<13498 16550 23186 23621 18818 18211>,
			<13627 17839 22157 24973 20364 19819>,
			<13818 19745 21428 26014 22014 21380>,
			<13965 20855 21646 25466 22693 21933>,
			<14181 21712 22343 23925 23172 22238>,
			<14353 22240 22584 23378 23703 22637>,
			<14375 21495 21996 23965 24673 23219>,
			<14371 19935 21310 24558 25380 23883>,
			<14335 18255 21094 24484 25432 24800>,
			<13972 15409 20976 24021 25546 25918>,
			<13541 14761 20622 22495 25230 25775>,
			<13195 14533 20004 20923 23635 23907>,
			<13130 14309 20168 21050 20307 17321>,
			<13183 14274 19664 21214 18222 16027>,
			<13133 13930 19092 20395 16990 15279>,
			<13125 13997 18880 19801 16354 15163>,
			<13365 14304 18729 19175 16185 14941>,
			<13118 14355 17203 19837 16924 15262>,
			<11743 14052 15278 21547 17648 16056>,
			<10056 11336 14439 21112 17348 16364>,
			<9157 9248 13210 22226 20009 19272>,
			<9157 9248 13210 22226 20009 19272>,
			<9157 9248 13210 22226 20009 19272>;
	};

	qcom,pc-temp-y6-lut {
		qcom,lut-col-legend = <(-10) 0 10 25 40 50>;
		qcom,lut-row-legend = <10000 9800 9600 9400 9200 9000>,
			<8800 8600 8400 8200 8000 7800>,
			<7600 7400 7200 7000 6800 6600>,
			<6400 6200 6000 5800 5600 5400>,
			<5200 5000 4800 4600 4400 4200>,
			<4000 3800 3600 3400 3200 3000>,
			<2800 2600 2400 2200 2000 1800>,
			<1600 1400 1200 1000 900 800>,
			<700 600 500 400 300 200>,
			<100 0>;
		qcom,lut-data = <5544 5237 5108 5020 4993 4989>,
			<5554 5251 5116 5020 4994 4990>,
			<5564 5263 5121 5021 4995 4991>,
			<5573 5272 5124 5021 4996 4993>,
			<5580 5279 5126 5022 4997 4994>,
			<5583 5282 5127 5022 4997 4995>,
			<5581 5279 5125 5022 4998 4995>,
			<5577 5275 5122 5022 4998 4995>,
			<5576 5271 5120 5022 4998 4995>,
			<5577 5268 5118 5023 4999 4996>,
			<5578 5267 5116 5023 4999 4996>,
			<5578 5267 5117 5024 4999 4996>,
			<5578 5269 5117 5025 5000 4996>,
			<5580 5272 5118 5027 5001 4996>,
			<5595 5279 5121 5029 5002 4997>,
			<5610 5288 5125 5031 5004 4999>,
			<5595 5294 5132 5034 5006 5000>,
			<5546 5299 5142 5038 5008 5001>,
			<5514 5299 5146 5044 5012 5004>,
			<5505 5276 5146 5054 5020 5010>,
			<5498 5247 5144 5062 5026 5015>,
			<5490 5230 5131 5053 5020 5010>,
			<5481 5217 5105 5033 5007 5000>,
			<5474 5209 5092 5023 5000 4994>,
			<5468 5204 5086 5019 4996 4990>,
			<5463 5200 5083 5016 4994 4989>,
			<5464 5199 5082 5016 4994 4989>,
			<5475 5198 5082 5017 4994 4989>,
			<5490 5197 5082 5018 4994 4989>,
			<5505 5195 5083 5019 4996 4989>,
			<5523 5194 5083 5020 4998 4990>,
			<5543 5196 5083 5022 5000 4992>,
			<5566 5205 5082 5024 5003 4996>,
			<5591 5215 5081 5026 5005 4999>,
			<5619 5229 5083 5026 5006 5001>,
			<5650 5245 5086 5027 5007 5002>,
			<5684 5265 5090 5025 5005 5001>,
			<5723 5289 5096 5019 5001 4996>,
			<5764 5313 5103 5017 4999 4994>,
			<5806 5337 5109 5019 5001 4998>,
			<5849 5361 5116 5021 5004 5003>,
			<5896 5385 5126 5023 5004 5004>,
			<5944 5412 5140 5025 5004 5003>,
			<6003 5447 5153 5024 4999 4995>,
			<6084 5494 5170 5023 4994 4989>,
			<6198 5561 5191 5030 5005 5005>,
			<6264 5595 5191 5035 5017 5017>,
			<6335 5651 5214 5045 5029 5029>,
			<6470 5732 5245 5059 5040 5040>,
			<6683 5846 5285 5066 5043 5039>,
			<7168 6030 5326 5051 5017 5010>,
			<8660 6484 5394 5041 5009 5006>,
			<12462 8441 5569 5048 5012 5009>,
			<25471 17144 6201 5064 5019 5016>,
			<25471 17144 6201 5064 5019 5016>,
			<25471 17144 6201 5064 5019 5016>;
	};

};
